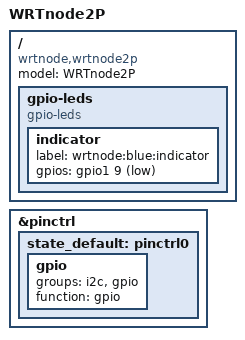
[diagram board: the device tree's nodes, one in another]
/dts-v1/;

#include "WRTNODE2.dtsi"

/ {
	compatible = "wrtnode,wrtnode2p", "wrtnode,wrtnode2", "mediatek,mt7628an-soc";
	model = "WRTnode2P";

	gpio-leds {
		compatible = "gpio-leds";

		indicator {
			label = "wrtnode:blue:indicator";
			gpios = <&gpio1 9 GPIO_ACTIVE_LOW>;
		};
	}; 
};

&pinctrl {
	state_default: pinctrl0 {
		gpio {
			groups = "i2c", "gpio";
			function = "gpio";
		};
	};
};
